AUTOSAR XML (schema 00046)
package /ComponentTypes
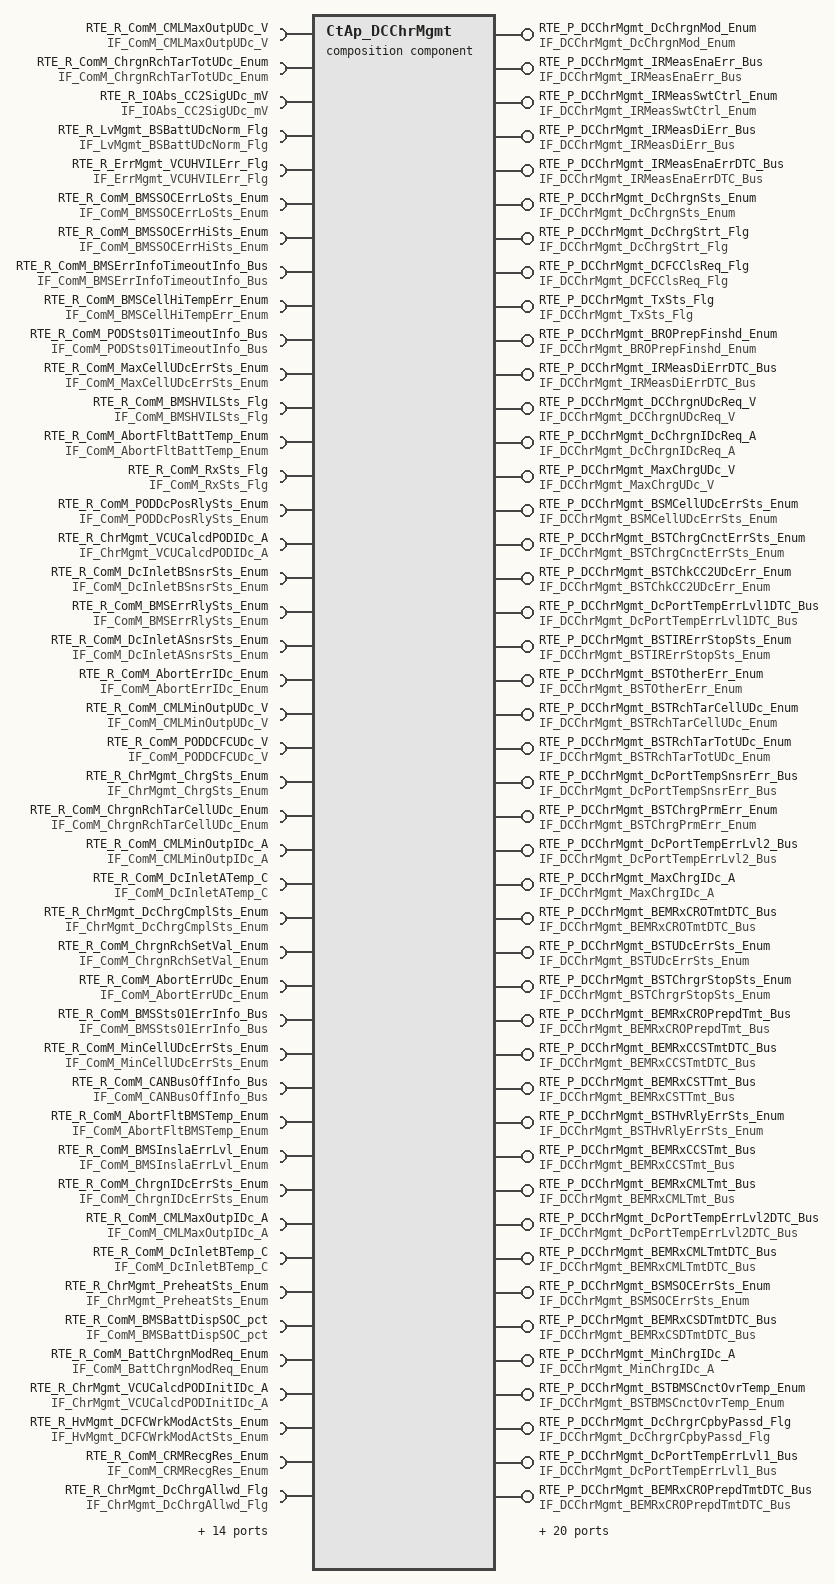
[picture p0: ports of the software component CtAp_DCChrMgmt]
  composition sw component type CtAp_DCChrMgmt
    14 x provide port:
      RTE_P_DCChrMgmt_DcChrgnMod_Enum: nonqueued-sender-com-spec{data-element=tec_DCChrMgmt_DcChrgnMod_Enum, init-value=0}, provided-interface=IF_DCChrMgmt_DcChrgnMod_Enum
      RTE_P_DCChrMgmt_IRMeasEnaErr_Bus: nonqueued-sender-com-spec{data-element=tec_DCChrMgmt_IRMeasEnaErr_Bus, init-value=fields=[DCChrMgmt_MonStatIRMeasEnaErr:0, DCChrMgmt_MonResIRMeasEnaErr:0, DCChrMgmt_ErrStatIRMeasEnaErr:0, DCChrMgmt_ErrResIRMeasEnaErr:0]}, provided-interface=IF_DCChrMgmt_IRMeasEnaErr_Bus
      RTE_P_DCChrMgmt_IRMeasSwtCtrl_Enum: nonqueued-sender-com-spec{data-element=tec_DCChrMgmt_IRMeasSwtCtrl_Enum, init-value=0}, provided-interface=IF_DCChrMgmt_IRMeasSwtCtrl_Enum
      RTE_P_DCChrMgmt_IRMeasDiErr_Bus: nonqueued-sender-com-spec{data-element=tec_DCChrMgmt_IRMeasDiErr_Bus, init-value=fields=[DCChrMgmt_MonStatIRMeasDiErr:0, DCChrMgmt_MonResIRMeasDiErr:0, DCChrMgmt_ErrStatIRMeasDiErr:0, DCChrMgmt_ErrResIRMeasDiErr:0]}, provided-interface=IF_DCChrMgmt_IRMeasDiErr_Bus
      RTE_P_DCChrMgmt_IRMeasEnaErrDTC_Bus: nonqueued-sender-com-spec{data-element=tec_DCChrMgmt_IRMeasEnaErrDTC_Bus, init-value=fields=[DCChrMgmt_MonStatIRMeasEnaErrDTC:0, DCChrMgmt_MonResIRMeasEnaErrDTC:0, DCChrMgmt_ErrStatIRMeasEnaErrDTC:0, DCChrMgmt_ErrResIRMeasEnaErrDTC:0]}, provided-interface=IF_DCChrMgmt_IRMeasEnaErrDTC_Bus
      RTE_P_DCChrMgmt_DcChrgnSts_Enum: nonqueued-sender-com-spec{data-element=tec_DCChrMgmt_DcChrgnSts_Enum, init-value=0}, provided-interface=IF_DCChrMgmt_DcChrgnSts_Enum
      RTE_P_DCChrMgmt_DcChrgStrt_Flg: nonqueued-sender-com-spec{data-element=tec_DCChrMgmt_DcChrgStrt_Flg, init-value=0}, provided-interface=IF_DCChrMgmt_DcChrgStrt_Flg
      RTE_P_DCChrMgmt_DCFCClsReq_Flg: nonqueued-sender-com-spec{data-element=tec_DCChrMgmt_DCFCClsReq_Flg, init-value=0}, provided-interface=IF_DCChrMgmt_DCFCClsReq_Flg
      RTE_P_DCChrMgmt_TxSts_Flg: provided-interface=IF_DCChrMgmt_TxSts_Flg
        provided-com-specs:
          data-element=tec_DCChrMgmt_TxBSDSts_Flg, init-value=0
          data-element=tec_DCChrMgmt_TxBEMSts_Flg, init-value=0
          data-element=tec_DCChrMgmt_TxBSMSts_Flg, init-value=0
          data-element=tec_DCChrMgmt_TxBCSSts_Flg, init-value=0
          data-element=tec_DCChrMgmt_TxBSTSts_Flg, init-value=0
          data-element=tec_DCChrMgmt_TxBCLSts_Flg, init-value=0
          data-element=tec_DCChrMgmt_TxBROSts_Flg, init-value=0
          data-element=tec_DCChrMgmt_TxBCPSts_Flg, init-value=0
          data-element=tec_DCChrMgmt_TxBRMSts_Flg, init-value=0
          data-element=tec_DCChrMgmt_TxBHMSts_Flg, init-value=0
      RTE_P_DCChrMgmt_BROPrepFinshd_Enum: nonqueued-sender-com-spec{data-element=tec_DCChrMgmt_BROPrepFinshd_Enum, init-value=0}, provided-interface=IF_DCChrMgmt_BROPrepFinshd_Enum
      RTE_P_DCChrMgmt_IRMeasDiErrDTC_Bus: nonqueued-sender-com-spec{data-element=tec_DCChrMgmt_IRMeasDiErrDTC_Bus, init-value=fields=[DCChrMgmt_MonStatIRMeasDiErrDTC:0, DCChrMgmt_MonResIRMeasDiErrDTC:0, DCChrMgmt_ErrStatIRMeasDiErrDTC:0, DCChrMgmt_ErrResIRMeasDiErrDTC:0]}, provided-interface=IF_DCChrMgmt_IRMeasDiErrDTC_Bus
      RTE_P_DCChrMgmt_DCChrgnUDcReq_V: nonqueued-sender-com-spec{data-element=tec_DCChrMgmt_DcChrgnUDcReq_V, init-value=0}, provided-interface=IF_DCChrMgmt_DCChrgnUDcReq_V
      RTE_P_DCChrMgmt_DcChrgnIDcReq_A: nonqueued-sender-com-spec{data-element=tec_DCChrMgmt_DcChrgnIDcReq_A, init-value=0}, provided-interface=IF_DCChrMgmt_DcChrgnIDcReq_A
      RTE_P_DCChrMgmt_MaxChrgUDc_V: nonqueued-sender-com-spec{data-element=tec_DCChrMgmt_MaxChrgUDc_V, init-value=0}, provided-interface=IF_DCChrMgmt_MaxChrgUDc_V
    require port RTE_R_ComM_CMLMaxOutpUDc_V: nonqueued-receiver-com-spec{data-element=tec_ComM_CMLMaxOutpUDc_V, filter=data-filter-type=ALWAYS, init-value=0}, required-interface=IF_ComM_CMLMaxOutpUDc_V
    4 x provide port:
      RTE_P_DCChrMgmt_BSMCellUDcErrSts_Enum: nonqueued-sender-com-spec{data-element=tec_DCChrMgmt_BSMCellUDcErrSts_Enum, init-value=0}, provided-interface=IF_DCChrMgmt_BSMCellUDcErrSts_Enum
      RTE_P_DCChrMgmt_BSTChrgCnctErrSts_Enum: nonqueued-sender-com-spec{data-element=tec_DCChrMgmt_BSTChrgCnctErrSts_Enum, init-value=0}, provided-interface=IF_DCChrMgmt_BSTChrgCnctErrSts_Enum
      RTE_P_DCChrMgmt_BSTChkCC2UDcErr_Enum: nonqueued-sender-com-spec{data-element=tec_DCChrMgmt_BSTChkCC2UDcErr_Enum, init-value=0}, provided-interface=IF_DCChrMgmt_BSTChkCC2UDcErr_Enum
      RTE_P_DCChrMgmt_DcPortTempErrLvl1DTC_Bus: nonqueued-sender-com-spec{data-element=tec_DCChrMgmt_DcPortTempErrLvl1DTC_Bus, init-value=fields=[DCChrMgmt_MonStatDcPortTempErrLvl1DTC:0, DCChrMgmt_MonResDcPortTempErrLvl1DTC:0, DCChrMgmt_ErrStatDcPortTempErrLvl1DTC:0, DCChrMgmt_ErrResDcPortTempErrLvl1DTC:0]}, provided-interface=IF_DCChrMgmt_DcPortTempErrLvl1DTC_Bus
    require port RTE_R_ComM_ChrgnRchTarTotUDc_Enum: nonqueued-receiver-com-spec{data-element=tec_ComM_ChrgnRchTarTotUDc_Enum, filter=data-filter-type=ALWAYS, init-value=0}, required-interface=IF_ComM_ChrgnRchTarTotUDc_Enum
    provide port RTE_P_DCChrMgmt_BSTIRErrStopSts_Enum: nonqueued-sender-com-spec{data-element=tec_DCChrMgmt_BSTIRErrStopSts_Enum, init-value=0}, provided-interface=IF_DCChrMgmt_BSTIRErrStopSts_Enum
    provide port RTE_P_DCChrMgmt_BSTOtherErr_Enum: nonqueued-sender-com-spec{data-element=tec_DCChrMgmt_BSTOtherErr_Enum, init-value=0}, provided-interface=IF_DCChrMgmt_BSTOtherErr_Enum
    require port RTE_R_IOAbs_CC2SigUDc_mV: nonqueued-receiver-com-spec{data-element=tec_IOAbs_CC2SigUDc_mV, filter=data-filter-type=ALWAYS, init-value=0}, required-interface=IF_IOAbs_CC2SigUDc_mV
    provide port RTE_P_DCChrMgmt_BSTRchTarCellUDc_Enum: nonqueued-sender-com-spec{data-element=tec_DCChrMgmt_BSTRchTarCellUDc_Enum, init-value=0}, provided-interface=IF_DCChrMgmt_BSTRchTarCellUDc_Enum
    provide port RTE_P_DCChrMgmt_BSTRchTarTotUDc_Enum: nonqueued-sender-com-spec{data-element=tec_DCChrMgmt_BSTRchTarTotUDc_Enum, init-value=0}, provided-interface=IF_DCChrMgmt_BSTRchTarTotUDc_Enum
    require port RTE_R_LvMgmt_BSBattUDcNorm_Flg: nonqueued-receiver-com-spec{data-element=tec_LvMgmt_BSBattUDcNorm_Flg, filter=data-filter-type=ALWAYS, init-value=0}, required-interface=IF_LvMgmt_BSBattUDcNorm_Flg
    provide port RTE_P_DCChrMgmt_DcPortTempSnsrErr_Bus: nonqueued-sender-com-spec{data-element=tec_DCChrMgmt_DcPortTempSnsrErr_Bus, init-value=fields=[DCChrMgmt_MonStatDcPortTempSnsrErr:0, DCChrMgmt_MonResDcPortTempSnsrErr:0, DCChrMgmt_ErrStatDcPortTempSnsrErr:0, DCChrMgmt_ErrResDcPortTempSnsrErr:0]}, provided-interface=IF_DCChrMgmt_DcPortTempSnsrErr_Bus
    provide port RTE_P_DCChrMgmt_BSTChrgPrmErr_Enum: nonqueued-sender-com-spec{data-element=tec_DCChrMgmt_BSTChrgPrmErr_Enum, init-value=0}, provided-interface=IF_DCChrMgmt_BSTChrgPrmErr_Enum
    require port RTE_R_ErrMgmt_VCUHVILErr_Flg: nonqueued-receiver-com-spec{data-element=tec_ErrMgmt_VCUHVILErr_Flg, filter=data-filter-type=ALWAYS, init-value=0}, required-interface=IF_ErrMgmt_VCUHVILErr_Flg
    require port RTE_R_ComM_BMSSOCErrLoSts_Enum: nonqueued-receiver-com-spec{data-element=tec_ComM_BMSSOCLoErrSts_Enum, filter=data-filter-type=ALWAYS, init-value=0}, required-interface=IF_ComM_BMSSOCErrLoSts_Enum
    4 x provide port:
      RTE_P_DCChrMgmt_DcPortTempErrLvl2_Bus: nonqueued-sender-com-spec{data-element=tec_DCChrMgmt_DcPortTempErrLvl2_Bus, init-value=fields=[DCChrMgmt_MonStatDcPortTempErrLvl2:0, DCChrMgmt_MonResDcPortTempErrLvl2:0, DCChrMgmt_ErrStatDcPortTempErrLvl2:0, DCChrMgmt_ErrResDcPortTempErrLvl2:0]}, provided-interface=IF_DCChrMgmt_DcPortTempErrLvl2_Bus
      RTE_P_DCChrMgmt_MaxChrgIDc_A: nonqueued-sender-com-spec{data-element=tec_DCChrMgmt_MaxChrgIDc_A, init-value=0}, provided-interface=IF_DCChrMgmt_MaxChrgIDc_A
      RTE_P_DCChrMgmt_BEMRxCROTmtDTC_Bus: nonqueued-sender-com-spec{data-element=tec_DCChrMgmt_BEMRxCROTmtDTC_Bus, init-value=fields=[DCChrMgmt_MonStatBEMRxCROTmtDTC:0, DCChrMgmt_MonResBEMRxCROTmtDTC:0, DCChrMgmt_ErrStatBEMRxCROTmtDTC:0, DCChrMgmt_ErrResBEMRxCROTmtDTC:0]}, provided-interface=IF_DCChrMgmt_BEMRxCROTmtDTC_Bus
      RTE_P_DCChrMgmt_BSTUDcErrSts_Enum: nonqueued-sender-com-spec{data-element=tec_DCChrMgmt_BSTUDcErrSts_Enum, init-value=0}, provided-interface=IF_DCChrMgmt_BSTUDcErrSts_Enum
    require port RTE_R_ComM_BMSSOCErrHiSts_Enum: nonqueued-receiver-com-spec{data-element=tec_ComM_BMSSOCHiErrSts_Enum, filter=data-filter-type=ALWAYS, init-value=0}, required-interface=IF_ComM_BMSSOCErrHiSts_Enum
    provide port RTE_P_DCChrMgmt_BSTChrgrStopSts_Enum: nonqueued-sender-com-spec{data-element=tec_DCChrMgmt_BSTChrgrStopSts_Enum, init-value=0}, provided-interface=IF_DCChrMgmt_BSTChrgrStopSts_Enum
    provide port RTE_P_DCChrMgmt_BEMRxCROPrepdTmt_Bus: nonqueued-sender-com-spec{data-element=tec_DCChrMgmt_BEMRxCROPrepdTmt_Bus, init-value=fields=[DCChrMgmt_MonStatBEMRxCROPrepdTmt:0, DCChrMgmt_MonResBEMRxCROPrepdTmt:0, DCChrMgmt_ErrStatBEMRxCROPrepdTmt:0, DCChrMgmt_ErrResBEMRxCROPrepdTmt:0]}, provided-interface=IF_DCChrMgmt_BEMRxCROPrepdTmt_Bus
    require port RTE_R_ComM_BMSErrInfoTimeoutInfo_Bus: nonqueued-receiver-com-spec{data-element=tec_ComM_BMSErrInfoTimeoutInfo_Bus, filter=data-filter-type=ALWAYS, init-value=fields=[ComM_MonStatBMSErrInfoTimeoutInfo:0, ComM_MonResBMSErrInfoTimeoutInfo:0, ComM_ErrStatBMSErrInfoTimeoutInfo:0, ComM_ErrResBMSErrInfoTimeoutInfo:0]}, required-interface=IF_ComM_BMSErrInfoTimeoutInfo_Bus
    provide port RTE_P_DCChrMgmt_BEMRxCCSTmtDTC_Bus: nonqueued-sender-com-spec{data-element=tec_DCChrMgmt_BEMRxCCSTmtDTC_Bus, init-value=fields=[DCChrMgmt_MonStatBEMRxCCSTmtDTC:0, DCChrMgmt_MonResBEMRxCCSTmtDTC:0, DCChrMgmt_ErrStatBEMRxCCSTmtDTC:0, DCChrMgmt_ErrResBEMRxCCSTmtDTC:0]}, provided-interface=IF_DCChrMgmt_BEMRxCCSTmtDTC_Bus
    provide port RTE_P_DCChrMgmt_BEMRxCSTTmt_Bus: nonqueued-sender-com-spec{data-element=tec_DCChrMgmt_BEMRxCSTTmt_Bus, init-value=fields=[DCChrMgmt_MonStatBEMRxCSTTmt:0, DCChrMgmt_MonResBEMRxCSTTmt:0, DCChrMgmt_ErrStatBEMRxCSTTmt:0, DCChrMgmt_ErrResBEMRxCSTTmt:0]}, provided-interface=IF_DCChrMgmt_BEMRxCSTTmt_Bus
    4 x require port:
      RTE_R_ComM_BMSCellHiTempErr_Enum: nonqueued-receiver-com-spec{data-element=tec_ComM_BMSCellHiTempErr_Enum, filter=data-filter-type=ALWAYS, init-value=0}, required-interface=IF_ComM_BMSCellHiTempErr_Enum
      RTE_R_ComM_PODSts01TimeoutInfo_Bus: nonqueued-receiver-com-spec{data-element=tec_ComM_PODSts01TimeoutInfo_Bus, filter=data-filter-type=ALWAYS, init-value=fields=[ComM_MonStatPODSts01TimeoutInfo:0, ComM_MonResPODSts01TimeoutInfo:0, ComM_ErrStatPODSts01TimeoutInfo:0, ComM_ErrResPODSts01TimeoutInfo:0]}, required-interface=IF_ComM_PODSts01TimeoutInfo_Bus
      RTE_R_ComM_MaxCellUDcErrSts_Enum: nonqueued-receiver-com-spec{data-element=tec_ComM_MaxCellUDcErrSts_Enum, filter=data-filter-type=ALWAYS, init-value=0}, required-interface=IF_ComM_MaxCellUDcErrSts_Enum
      RTE_R_ComM_BMSHVILSts_Flg: nonqueued-receiver-com-spec{data-element=tec_ComM_BMSHVILSts_Flg, filter=data-filter-type=ALWAYS, init-value=0}, required-interface=IF_ComM_BMSHVILSts_Flg
    provide port RTE_P_DCChrMgmt_BSTHvRlyErrSts_Enum: nonqueued-sender-com-spec{data-element=tec_DCChrMgmt_BSTHvRlyErrSts_Enum, init-value=0}, provided-interface=IF_DCChrMgmt_BSTHvRlyErrSts_Enum
    provide port RTE_P_DCChrMgmt_BEMRxCCSTmt_Bus: nonqueued-sender-com-spec{data-element=tec_DCChrMgmt_BEMRxCCSTmt_Bus, init-value=fields=[DCChrMgmt_MonStatBEMRxCCSTmt:0, DCChrMgmt_MonResBEMRxCCSTmt:0, DCChrMgmt_ErrStatBEMRxCCSTmt:0, DCChrMgmt_ErrResBEMRxCCSTmt:0]}, provided-interface=IF_DCChrMgmt_BEMRxCCSTmt_Bus
    provide port RTE_P_DCChrMgmt_BEMRxCMLTmt_Bus: nonqueued-sender-com-spec{data-element=tec_DCChrMgmt_BEMRxCMLTmt_Bus, init-value=fields=[DCChrMgmt_MonStatBEMRxCMLTmt:0, DCChrMgmt_MonResBEMRxCMLTmt:0, DCChrMgmt_ErrStatBEMRxCMLTmt:0, DCChrMgmt_ErrResBEMRxCMLTmt:0]}, provided-interface=IF_DCChrMgmt_BEMRxCMLTmt_Bus
    require port RTE_R_ComM_AbortFltBattTemp_Enum: nonqueued-receiver-com-spec{data-element=tec_ComM_AbortFltBattTemp_Enum, filter=data-filter-type=ALWAYS, init-value=0}, required-interface=IF_ComM_AbortFltBattTemp_Enum
    require port RTE_R_ComM_RxSts_Flg: required-interface=IF_ComM_RxSts_Flg
      required-com-specs:
        data-element=tec_ComM_RxCROSts_Flg, filter=data-filter-type=ALWAYS, init-value=0
        data-element=tec_ComM_RxCEMSts_Flg, filter=data-filter-type=ALWAYS, init-value=0
        data-element=tec_ComM_RxCHMSts_Flg, filter=data-filter-type=ALWAYS, init-value=0
        data-element=tec_ComM_RxCSTSts_Flg, filter=data-filter-type=ALWAYS, init-value=0
        data-element=tec_ComM_RxCSDSts_Flg, filter=data-filter-type=ALWAYS, init-value=0
        data-element=tec_ComM_RxCCSSts_Flg, filter=data-filter-type=ALWAYS, init-value=0
        data-element=tec_ComM_RxCMLSts_Flg, filter=data-filter-type=ALWAYS, init-value=0
        data-element=tec_ComM_RxCRMSts_Flg, filter=data-filter-type=ALWAYS, init-value=0
    require port RTE_R_ComM_PODDcPosRlySts_Enum: nonqueued-receiver-com-spec{data-element=tec_ComM_PODDcPosRlySts_Enum, filter=data-filter-type=ALWAYS, init-value=0}, required-interface=IF_ComM_PODDcPosRlySts_Enum
    provide port RTE_P_DCChrMgmt_DcPortTempErrLvl2DTC_Bus: nonqueued-sender-com-spec{data-element=tec_DCChrMgmt_DcPortTempErrLvl2DTC_Bus, init-value=fields=[DCChrMgmt_MonStatDcPortTempErrLvl2DTC:0, DCChrMgmt_MonResDcPortTempErrLvl2DTC:0, DCChrMgmt_ErrStatDcPortTempErrLvl2DTC:0, DCChrMgmt_ErrResDcPortTempErrLvl2DTC:0]}, provided-interface=IF_DCChrMgmt_DcPortTempErrLvl2DTC_Bus
    provide port RTE_P_DCChrMgmt_BEMRxCMLTmtDTC_Bus: nonqueued-sender-com-spec{data-element=tec_DCChrMgmt_BEMRxCMLTmtDTC_Bus, init-value=fields=[DCChrMgmt_MonStatBEMRxCMLTmtDTC:0, DCChrMgmt_MonResBEMRxCMLTmtDTC:0, DCChrMgmt_ErrStatBEMRxCMLTmtDTC:0, DCChrMgmt_ErrResBEMRxCMLTmtDTC:0]}, provided-interface=IF_DCChrMgmt_BEMRxCMLTmtDTC_Bus
    require port RTE_R_ChrMgmt_VCUCalcdPODIDc_A: nonqueued-receiver-com-spec{data-element=tec_ChrMgmt_VCUCalcdPODIDc_A, filter=data-filter-type=ALWAYS, init-value=0}, required-interface=IF_ChrMgmt_VCUCalcdPODIDc_A
    require port RTE_R_ComM_DcInletBSnsrSts_Enum: nonqueued-receiver-com-spec{data-element=tec_ComM_DcInletBSnsrSts_Enum, filter=data-filter-type=ALWAYS, init-value=0}, required-interface=IF_ComM_DcInletBSnsrSts_Enum
    provide port RTE_P_DCChrMgmt_BSMSOCErrSts_Enum: nonqueued-sender-com-spec{data-element=tec_DCChrMgmt_BSMSOCErrSts_Enum, init-value=0}, provided-interface=IF_DCChrMgmt_BSMSOCErrSts_Enum
    require port RTE_R_ComM_BMSErrRlySts_Enum: nonqueued-receiver-com-spec{data-element=tec_ComM_BMSErrRlySts_Enum, filter=data-filter-type=ALWAYS, init-value=0}, required-interface=IF_ComM_BMSErrRlySts_Enum
    require port RTE_R_ComM_DcInletASnsrSts_Enum: nonqueued-receiver-com-spec{data-element=tec_ComM_DcInletASnsrSts_Enum, filter=data-filter-type=ALWAYS, init-value=0}, required-interface=IF_ComM_DcInletASnsrSts_Enum
    provide port RTE_P_DCChrMgmt_BEMRxCSDTmtDTC_Bus: nonqueued-sender-com-spec{data-element=tec_DCChrMgmt_BEMRxCSDTmtDTC_Bus, init-value=fields=[DCChrMgmt_MonStatBEMRxCSDTmtDTC:0, DCChrMgmt_MonResBEMRxCSDTmtDTC:0, DCChrMgmt_ErrStatBEMRxCSDTmtDTC:0, DCChrMgmt_ErrResBEMRxCSDTmtDTC:0]}, provided-interface=IF_DCChrMgmt_BEMRxCSDTmtDTC_Bus
    require port RTE_R_ComM_AbortErrIDc_Enum: nonqueued-receiver-com-spec{data-element=tec_ComM_AbortErrIDc_Enum, filter=data-filter-type=ALWAYS, init-value=0}, required-interface=IF_ComM_AbortErrIDc_Enum
    require port RTE_R_ComM_CMLMinOutpUDc_V: nonqueued-receiver-com-spec{data-element=tec_ComM_CMLMinOutpUDc_V, filter=data-filter-type=ALWAYS, init-value=0}, required-interface=IF_ComM_CMLMinOutpUDc_V
    require port RTE_R_ComM_PODDCFCUDc_V: nonqueued-receiver-com-spec{data-element=tec_ComM_PODDCFCUDc_V, filter=data-filter-type=ALWAYS, init-value=0}, required-interface=IF_ComM_PODDCFCUDc_V
    provide port RTE_P_DCChrMgmt_MinChrgIDc_A: nonqueued-sender-com-spec{data-element=tec_DCChrMgmt_MinChrgIDc_A, init-value=0}, provided-interface=IF_DCChrMgmt_MinChrgIDc_A
    require port RTE_R_ChrMgmt_ChrgSts_Enum: nonqueued-receiver-com-spec{data-element=tec_ChrMgmt_ChrgSts_Enum, filter=data-filter-type=ALWAYS, init-value=0}, required-interface=IF_ChrMgmt_ChrgSts_Enum
    provide port RTE_P_DCChrMgmt_BSTBMSCnctOvrTemp_Enum: nonqueued-sender-com-spec{data-element=tec_DCChrMgmt_BSTBMSCnctOvrTemp_Enum, init-value=0}, provided-interface=IF_DCChrMgmt_BSTBMSCnctOvrTemp_Enum
    require port RTE_R_ComM_ChrgnRchTarCellUDc_Enum: nonqueued-receiver-com-spec{data-element=tec_ComM_ChrgnRchTarCellUDc_Enum, filter=data-filter-type=ALWAYS, init-value=0}, required-interface=IF_ComM_ChrgnRchTarCellUDc_Enum
    require port RTE_R_ComM_CMLMinOutpIDc_A: nonqueued-receiver-com-spec{data-element=tec_ComM_CMLMinOutpIDc_A, filter=data-filter-type=ALWAYS, init-value=0}, required-interface=IF_ComM_CMLMinOutpIDc_A
    provide port RTE_P_DCChrMgmt_DcChrgrCpbyPassd_Flg: nonqueued-sender-com-spec{data-element=tec_DCChrMgmt_DcChrgrCpbyPassd_Flg, init-value=0}, provided-interface=IF_DCChrMgmt_DcChrgrCpbyPassd_Flg
    provide port RTE_P_DCChrMgmt_DcPortTempErrLvl1_Bus: nonqueued-sender-com-spec{data-element=tec_DCChrMgmt_DcPortTempErrLvl1_Bus, init-value=fields=[DCChrMgmt_MonStatDcPortTempErrLvl1:0, DCChrMgmt_MonResDcPortTempErrLvl1:0, DCChrMgmt_ErrStatDcPortTempErrLvl1:0, DCChrMgmt_ErrResDcPortTempErrLvl1:0]}, provided-interface=IF_DCChrMgmt_DcPortTempErrLvl1_Bus
    require port RTE_R_ComM_DcInletATemp_C: nonqueued-receiver-com-spec{data-element=tec_ComM_DcInletATemp_C, filter=data-filter-type=ALWAYS, init-value=0}, required-interface=IF_ComM_DcInletATemp_C
    provide port RTE_P_DCChrMgmt_BEMRxCROPrepdTmtDTC_Bus: nonqueued-sender-com-spec{data-element=tec_DCChrMgmt_BEMRxCROPrepdTmtDTC_Bus, init-value=fields=[DCChrMgmt_MonStatBEMRxCROPrepdTmtDTC:0, DCChrMgmt_MonResBEMRxCROPrepdTmtDTC:0, DCChrMgmt_ErrStatBEMRxCROPrepdTmtDTC:0, DCChrMgmt_ErrResBEMRxCROPrepdTmtDTC:0]}, provided-interface=IF_DCChrMgmt_BEMRxCROPrepdTmtDTC_Bus
    require port RTE_R_ChrMgmt_DcChrgCmplSts_Enum: nonqueued-receiver-com-spec{data-element=tec_ChrMgmt_DcChrgCmplSts_Enum, filter=data-filter-type=ALWAYS, init-value=0}, required-interface=IF_ChrMgmt_DcChrgCmplSts_Enum
    provide port RTE_P_DCChrMgmt_BSTOutpCnctOvrTemp_Enum: nonqueued-sender-com-spec{data-element=tec_DCChrMgmt_BSTOutpCnctOvrTemp_Enum, init-value=0}, provided-interface=IF_DCChrMgmt_BSTOutpCnctOvrTemp_Enum
    provide port RTE_P_DCChrMgmt_BEMRxCSDTmt_Bus: nonqueued-sender-com-spec{data-element=tec_DCChrMgmt_BEMRxCSDTmt_Bus, init-value=fields=[DCChrMgmt_MonStatBEMRxCSDTmt:0, DCChrMgmt_MonResBEMRxCSDTmt:0, DCChrMgmt_ErrStatBEMRxCSDTmt:0, DCChrMgmt_ErrResBEMRxCSDTmt:0]}, provided-interface=IF_DCChrMgmt_BEMRxCSDTmt_Bus
    require port RTE_R_ComM_ChrgnRchSetVal_Enum: nonqueued-receiver-com-spec{data-element=tec_ComM_ChrgnRchSetVal_Enum, filter=data-filter-type=ALWAYS, init-value=0}, required-interface=IF_ComM_ChrgnRchSetVal_Enum
    7 x provide port:
      RTE_P_DCChrMgmt_MinChrgUDc_V: nonqueued-sender-com-spec{data-element=tec_DCChrMgmt_MinChrgUDc_V, init-value=0}, provided-interface=IF_DCChrMgmt_MinChrgUDc_V
      RTE_P_DCChrMgmt_BSTRchTarSOC_Enum: nonqueued-sender-com-spec{data-element=tec_DCChrMgmt_BSTRchTarSOC_Enum, init-value=0}, provided-interface=IF_DCChrMgmt_BSTRchTarSOC_Enum
      RTE_P_DCChrMgmt_BEMRxCRMPrepdTmtDTC_Bus: nonqueued-sender-com-spec{data-element=tec_DCChrMgmt_BEMRxCRMPrepdTmtDTC_Bus, init-value=fields=[DCChrMgmt_MonStatBEMRxCRMPrepdTmtDTC:0, DCChrMgmt_MonResBEMRxCRMPrepdTmtDTC:0, DCChrMgmt_ErrStatBEMRxCRMPrepdTmtDTC:0, DCChrMgmt_ErrResBEMRxCRMPrepdTmtDTC:0]}, provided-interface=IF_DCChrMgmt_BEMRxCRMPrepdTmtDTC_Bus
      RTE_P_DCChrMgmt_BSMOutpCnctErrSts_Enum: nonqueued-sender-com-spec{data-element=tec_DCChrMgmt_BSMOutpCnctErrSts_Enum, init-value=0}, provided-interface=IF_DCChrMgmt_BSMOutpCnctErrSts_Enum
      RTE_P_DCChrMgmt_BSTBattOvrTempErr_Enum: nonqueued-sender-com-spec{data-element=tec_DCChrMgmt_BSTBattOvrTempErr_Enum, init-value=0}, provided-interface=IF_DCChrMgmt_BSTBattOvrTempErr_Enum
      RTE_P_DCChrMgmt_BSMIRErrSts_Enum: nonqueued-sender-com-spec{data-element=tec_DCChrMgmt_BSMIRErrSts_Enum, init-value=0}, provided-interface=IF_DCChrMgmt_BSMIRErrSts_Enum
      RTE_P_DCChrMgmt_BSMBattTempHiErrSts_Enum: nonqueued-sender-com-spec{data-element=tec_DCChrMgmt_BSMBattTempHiErrSts_Enum, init-value=0}, provided-interface=IF_DCChrMgmt_BSMBattTempHiErrSts_Enum
    require port RTE_R_ComM_AbortErrUDc_Enum: nonqueued-receiver-com-spec{data-element=tec_ComM_AbortErrUDc_Enum, filter=data-filter-type=ALWAYS, init-value=0}, required-interface=IF_ComM_AbortErrUDc_Enum
    provide port RTE_P_DCChrMgmt_BSMChrgnIDcErrSts_Enum: nonqueued-sender-com-spec{data-element=tec_DCChrMgmt_BSMChrgnIDcErrSts_Enum, init-value=0}, provided-interface=IF_DCChrMgmt_BSMChrgnIDcErrSts_Enum
    provide port RTE_P_DCChrMgmt_BEMTxReqSts_Enum: nonqueued-sender-com-spec{data-element=tec_DCChrMgmt_BEMTxReqSts_Enum, init-value=0}, provided-interface=IF_DCChrMgmt_BEMTxReqSts_Enum
    require port RTE_R_ComM_BMSSts01ErrInfo_Bus: required-interface=IF_ComM_BMSSts01ErrInfo_Bus
      required-com-specs:
        data-element=tec_ComM_BMSSts01TimeoutInfo_Bus, filter=data-filter-type=ALWAYS, init-value=fields=[ComM_MonStatBMSSts01TimeoutInfo:0, ComM_MonResBMSSts01TimeoutInfo:0, ComM_ErrStatBMSSts01TimeoutInfo:0, ComM_ErrResBMSSts01TimeoutInfo:0]
        data-element=tec_ComM_BMSSts01CRCDTCInfo_Bus, filter=data-filter-type=ALWAYS, init-value=fields=[ComM_MonStatBMSSts01CRCDTCErrorInfo:0, ComM_MonResBMSSts01CRCDTCErrorInfo:0, ComM_ErrStatBMSSts01CRCDTCErrorInfo:0, ComM_ErrResBMSSts01CRCDTCErrorInfo:0]
        data-element=tec_ComM_BMSSts01CRCInfo_Bus, filter=data-filter-type=ALWAYS, init-value=fields=[ComM_MonStatBMSSts01CRCErrorInfo:0, ComM_MonResBMSSts01CRCErrorInfo:0, ComM_ErrStatBMSSts01CRCErrorInfo:0, ComM_ErrResBMSSts01CRCErrorInfo:0]
        data-element=tec_ComM_BMSSts01TimeoutDTCInfo_Bus, filter=data-filter-type=ALWAYS, init-value=fields=[ComM_MonStatBMSSts01TimeoutDTCErrorInfo:0, ComM_MonResBMSSts01TimeoutDTCErrorInfo:0, ComM_ErrStatBMSSts01TimeoutDTCErrorInfo:0, ComM_ErrResBMSSts01TimeoutDTCErrorInfo:0]
        data-element=tec_ComM_BMSSts01E2ETimeoutInfo_Bus, filter=data-filter-type=ALWAYS, init-value=fields=[ComM_MonStatBMSSts01E2ETimeoutInfo:0, ComM_MonResBMSSts01E2ETimeoutInfo:0, ComM_ErrStatBMSSts01E2ETimeoutInfo:0, ComM_ErrResBMSSts01E2ETimeoutInfo:0]
    require port RTE_R_ComM_MinCellUDcErrSts_Enum: nonqueued-receiver-com-spec{data-element=tec_ComM_MinCellUDcErrSts_Enum, filter=data-filter-type=ALWAYS, init-value=0}, required-interface=IF_ComM_MinCellUDcErrSts_Enum
    require port RTE_R_ComM_CANBusOffInfo_Bus: required-interface=IF_ComM_CANBusOffInfo_Bus
      required-com-specs:
        data-element=tec_ComM_EPTCANBusOffInfo_Bus, filter=data-filter-type=ALWAYS, init-value=fields=[ComM_MonStatEPTCANBusOffInfo:0, ComM_MonResEPTCANBusOffInfo:0, ComM_ErrStatEPTCANBusOffInfo:0, ComM_ErrResEPTCANBusOffInfo:0]
        data-element=tec_ComM_CHCANBusOffInfo_Bus, filter=data-filter-type=ALWAYS, init-value=fields=[ComM_MonStatCHCANBusOffInfo:0, ComM_MonResCHCANBusOffInfo:0, ComM_ErrStatCHCANBusOffInfo:0, ComM_ErrResCHCANBusOffInfo:0]
        data-element=tec_ComM_EPTCANBusOffDTCInfo_Bus, filter=data-filter-type=ALWAYS, init-value=fields=[ComM_MonStatEPTCANBusOffDTCInfo:0, ComM_MonResEPTCANBusOffDTCInfo:0, ComM_ErrStatEPTCANBusOffDTCInfo:0, ComM_ErrResEPTCANBusOffDTCInfo:0]
        data-element=tec_ComM_CHCANBusOffDTCInfo_Bus, filter=data-filter-type=ALWAYS, init-value=fields=[ComM_MonStatCHCANBusOffDTCInfo:0, ComM_MonResCHCANBusOffDTCInfo:0, ComM_ErrStatCHCANBusOffDTCInfo:0, ComM_ErrResCHCANBusOffDTCInfo:0]
    provide port RTE_P_DCChrMgmt_BEMRxCRMTmtDTC_Bus: nonqueued-sender-com-spec{data-element=tec_DCChrMgmt_BEMRxCRMTmtDTC_Bus, init-value=fields=[DCChrMgmt_MonStatBEMRxCRMTmtDTC:0, DCChrMgmt_MonResBEMRxCRMTmtDTC:0, DCChrMgmt_ErrStatBEMRxCRMTmtDTC:0, DCChrMgmt_ErrResBEMRxCRMTmtDTC:0]}, provided-interface=IF_DCChrMgmt_BEMRxCRMTmtDTC_Bus
    require port RTE_R_ComM_AbortFltBMSTemp_Enum: nonqueued-receiver-com-spec{data-element=tec_ComM_AbortFltBMSTemp_Enum, filter=data-filter-type=ALWAYS, init-value=0}, required-interface=IF_ComM_AbortFltBMSTemp_Enum
    provide port RTE_P_DCChrMgmt_BSTIDcErrSts_Enum: nonqueued-sender-com-spec{data-element=tec_DCChrMgmt_BSTIDcErrSts_Enum, init-value=0}, provided-interface=IF_DCChrMgmt_BSTIDcErrSts_Enum
    provide port RTE_P_DCChrMgmt_BEMRxCRMTmt_Bus: nonqueued-sender-com-spec{data-element=tec_DCChrMgmt_BEMRxCRMTmt_Bus, init-value=fields=[DCChrMgmt_MonStatBEMRxCRMTmt:0, DCChrMgmt_MonResBEMRxCRMTmt:0, DCChrMgmt_ErrStatBEMRxCRMTmt:0, DCChrMgmt_ErrResBEMRxCRMTmt:0]}, provided-interface=IF_DCChrMgmt_BEMRxCRMTmt_Bus
    require port RTE_R_ComM_BMSInslaErrLvl_Enum: nonqueued-receiver-com-spec{data-element=tec_ComM_BMSInslaErrLvl_Enum, filter=data-filter-type=ALWAYS, init-value=0}, required-interface=IF_ComM_BMSInslaErrLvl_Enum
    require port RTE_R_ComM_ChrgnIDcErrSts_Enum: nonqueued-receiver-com-spec{data-element=tec_ComM_ChrgnIDcErrSts_Enum, filter=data-filter-type=ALWAYS, init-value=0}, required-interface=IF_ComM_ChrgnIDcErrSts_Enum
    require port RTE_R_ComM_CMLMaxOutpIDc_A: nonqueued-receiver-com-spec{data-element=tec_ComM_CMLMaxOutpIDc_A, filter=data-filter-type=ALWAYS, init-value=0}, required-interface=IF_ComM_CMLMaxOutpIDc_A
    provide port RTE_P_DCChrMgmt_BEMRxCROTmt_Bus: nonqueued-sender-com-spec{data-element=tec_DCChrMgmt_BEMRxCROTmt_Bus, init-value=fields=[DCChrMgmt_MonStatBEMRxCROTmt:0, DCChrMgmt_MonResBEMRxCROTmt:0, DCChrMgmt_ErrStatBEMRxCROTmt:0, DCChrMgmt_ErrResBEMRxCROTmt:0]}, provided-interface=IF_DCChrMgmt_BEMRxCROTmt_Bus
    provide port RTE_P_DCChrMgmt_DcPortTempSnsrErrDTC_Bus: nonqueued-sender-com-spec{data-element=tec_DCChrMgmt_DcPortTempSnsrErrDTC_Bus, init-value=fields=[DCChrMgmt_MonStatDcPortTempSnsrErrDTC:0, DCChrMgmt_MonResDcPortTempSnsrErrDTC:0, DCChrMgmt_ErrStatDcPortTempSnsrErrDTC:0, DCChrMgmt_ErrResDcPortTempSnsrErrDTC:0]}, provided-interface=IF_DCChrMgmt_DcPortTempSnsrErrDTC_Bus
    require port RTE_R_ComM_DcInletBTemp_C: nonqueued-receiver-com-spec{data-element=tec_ComM_DcInletBTemp_C, filter=data-filter-type=ALWAYS, init-value=0}, required-interface=IF_ComM_DcInletBTemp_C
    provide port RTE_P_DCChrMgmt_BSMChrgAllwbl_Flg: nonqueued-sender-com-spec{data-element=tec_DCChrMgmt_BSMChrgAllwbl_Flg, init-value=0}, provided-interface=IF_DCChrMgmt_BSMChrgAllwbl_Flg
    provide port RTE_P_DCChrMgmt_BEMRxCRMPrepdTmt_Bus: nonqueued-sender-com-spec{data-element=tec_DCChrMgmt_BEMRxCRMPrepdTmt_Bus, init-value=fields=[DCChrMgmt_MonStatBEMRxCRMPrepdTmt:0, DCChrMgmt_MonResBEMRxCRMPrepdTmt:0, DCChrMgmt_ErrStatBEMRxCRMPrepdTmt:0, DCChrMgmt_ErrResBEMRxCRMPrepdTmt:0]}, provided-interface=IF_DCChrMgmt_BEMRxCRMPrepdTmt_Bus
    provide port RTE_P_DCChrMgmt_BEMRxCSTTmtDTC_Bus: nonqueued-sender-com-spec{data-element=tec_DCChrMgmt_BEMRxCSTTmtDTC_Bus, init-value=fields=[DCChrMgmt_MonStatBEMRxCSTTmtDTC:0, DCChrMgmt_MonResBEMRxCSTTmtDTC:0, DCChrMgmt_ErrStatBEMRxCSTTmtDTC:0, DCChrMgmt_ErrResBEMRxCSTTmtDTC:0]}, provided-interface=IF_DCChrMgmt_BEMRxCSTTmtDTC_Bus
    19 x require port:
      RTE_R_ChrMgmt_PreheatSts_Enum: nonqueued-receiver-com-spec{data-element=tec_ChrMgmt_PreheatSts_Enum, filter=data-filter-type=ALWAYS, init-value=0}, required-interface=IF_ChrMgmt_PreheatSts_Enum
      RTE_R_ComM_BMSBattDispSOC_pct: nonqueued-receiver-com-spec{data-element=tec_ComM_BMSBattDispSOC_pct, filter=data-filter-type=ALWAYS, init-value=0}, required-interface=IF_ComM_BMSBattDispSOC_pct
      RTE_R_ComM_BattChrgnModReq_Enum: nonqueued-receiver-com-spec{data-element=tec_ComM_BattChrgnModReq_Enum, filter=data-filter-type=ALWAYS, init-value=0}, required-interface=IF_ComM_BattChrgnModReq_Enum
      RTE_R_ChrMgmt_VCUCalcdPODInitIDc_A: nonqueued-receiver-com-spec{data-element=tec_ChrMgmt_VCUCalcdPODInitIDc_A, filter=data-filter-type=ALWAYS, init-value=0}, required-interface=IF_ChrMgmt_VCUCalcdPODInitIDc_A
      RTE_R_HvMgmt_DCFCWrkModActSts_Enum: nonqueued-receiver-com-spec{data-element=tec_HvMgmt_DCFCWrkModActSts_Enum, filter=data-filter-type=ALWAYS, init-value=0}, required-interface=IF_HvMgmt_DCFCWrkModActSts_Enum
      RTE_R_ComM_CRMRecgRes_Enum: nonqueued-receiver-com-spec{data-element=tec_ComM_CRMRecgRes_Enum, filter=data-filter-type=ALWAYS, init-value=0}, required-interface=IF_ComM_CRMRecgRes_Enum
      RTE_R_ChrMgmt_DcChrgAllwd_Flg: nonqueued-receiver-com-spec{data-element=tec_ChrMgmt_DcChrgAllwd_Flg, filter=data-filter-type=ALWAYS, init-value=0}, required-interface=IF_ChrMgmt_DcChrgAllwd_Flg
      RTE_R_ComM_BMSIRDetnSts_Enum: nonqueued-receiver-com-spec{data-element=tec_ComM_BMSIRDetnSts_Enum, filter=data-filter-type=ALWAYS, init-value=0}, required-interface=IF_ComM_BMSIRDetnSts_Enum
      RTE_R_ComM_CROPrepRdy_Enum: nonqueued-receiver-com-spec{data-element=tec_ComM_CROPrepRdy_Enum, filter=data-filter-type=ALWAYS, init-value=0}, required-interface=IF_ComM_CROPrepRdy_Enum
      RTE_R_ErrMgmt_DcPause_Flg: nonqueued-receiver-com-spec{data-element=tec_ErrMgmt_DcPause_Flg, filter=data-filter-type=ALWAYS, init-value=0}, required-interface=IF_ErrMgmt_DcPause_Flg
      RTE_R_ComM_BMSBattAllowChrgIDc_A: nonqueued-receiver-com-spec{data-element=tec_ComM_BMSBattAllowChrgIDc_A, filter=data-filter-type=ALWAYS, init-value=0}, required-interface=IF_ComM_BMSBattAllowChrgIDc_A
      RTE_R_ComM_BMSBattLnkUDc_V: nonqueued-receiver-com-spec{data-element=tec_ComM_BMSBattLnkUDc_V, filter=data-filter-type=ALWAYS, init-value=0}, required-interface=IF_ComM_BMSBattLnkUDc_V
      RTE_R_ComM_BMSBattPckUDc_V: nonqueued-receiver-com-spec{data-element=tec_ComM_BMSBattPckUDc_V, filter=data-filter-type=ALWAYS, init-value=0}, required-interface=IF_ComM_BMSBattPckUDc_V
      RTE_R_EgyMgmt_DCDCPwrCnsCalcn_Kw: nonqueued-receiver-com-spec{data-element=tec_EgyMgmt_DCDCPwrCnsCalcn_Kw, filter=data-filter-type=ALWAYS, init-value=0}, required-interface=IF_EgyMgmt_DCDCPwrCnsCalcn_Kw
      RTE_R_EgyMgmt_PackPTCPwrCnsCalcn_Kw: nonqueued-receiver-com-spec{data-element=tec_EgyMgmt_PackPTCPwrCnsCalcn_Kw, filter=data-filter-type=ALWAYS, init-value=0}, required-interface=IF_EgyMgmt_PackPTCPwrCnsCalcn_Kw
      RTE_R_EgyMgmt_ACSysPwrCnsCalcn_Kw: nonqueued-receiver-com-spec{data-element=tec_EgyMgmt_ACSysPwrCnsCalcn_Kw, filter=data-filter-type=ALWAYS, init-value=0}, required-interface=IF_EgyMgmt_ACSysPwrCnsCalcn_Kw
      RTE_R_ComM_BMSBattMaxChrgnUDc_V: nonqueued-receiver-com-spec{data-element=tec_ComM_BMSBattMaxChrgnUDc_V, filter=data-filter-type=ALWAYS, init-value=0}, required-interface=IF_ComM_BMSBattMaxChrgnUDc_V
      RTE_R_ModMgmt_HvSts_Enum: nonqueued-receiver-com-spec{data-element=tec_ModMgmt_HvSts_Enum, filter=data-filter-type=ALWAYS, init-value=0}, required-interface=IF_ModMgmt_HvSts_Enum
      RTE_R_DiagApp_DisableDCMReqInfo: nonqueued-receiver-com-spec{data-element=tec_DiagApp_DisableDCMReqInfo, filter=data-filter-type=ALWAYS, init-value=0}, required-interface=IF_DiagApp_DisableDCMReqInfo
    provide port RTE_P_DCChrMgmt_BSTTxReqSts: nonqueued-sender-com-spec{data-element=tec_DCChrMgmt_BSTTxReqSts, init-value=0}, provided-interface=IF_DCChrMgmt_BSTTxReqSts
    require port RTE_R_ComM_BMSNegRlySts_Enum: nonqueued-receiver-com-spec{data-element=tec_ComM_BMSNegRlySts_Enum, filter=data-filter-type=ALWAYS, init-value=0}, required-interface=IF_ComM_BMSNegRlySts_Enum
    require port RTE_R_ComM_BMSPosRlySts_Enum: nonqueued-receiver-com-spec{data-element=tec_ComM_BMSPosRlySts_Enum, filter=data-filter-type=ALWAYS, init-value=0}, required-interface=IF_ComM_BMSPosRlySts_Enum
    4 x component:
      CtAp_ChrgMod: type=CtAp_ChrgMod
      CtAp_DCParMgmt: type=CtAp_DCParMgmt
      CtAp_ChrgSeqCtrl: type=CtAp_ChrgSeqCtrl
      CtAp_ChrgComM: type=CtAp_ChrgComM
    delegate CtAp_ChrgMod.RTE_P_DCChrMgmt_DcChrgnMod_Enum <-> outer port RTE_P_DCChrMgmt_DcChrgnMod_Enum
    delegate CtAp_ChrgSeqCtrl.RTE_P_DCChrMgmt_IRMeasEnaErr_Bus <-> outer port RTE_P_DCChrMgmt_IRMeasEnaErr_Bus
    delegate CtAp_ChrgSeqCtrl.RTE_P_DCChrMgmt_IRMeasSwtCtrl_Enum <-> outer port RTE_P_DCChrMgmt_IRMeasSwtCtrl_Enum
    delegate CtAp_ChrgSeqCtrl.RTE_P_DCChrMgmt_IRMeasDiErr_Bus <-> outer port RTE_P_DCChrMgmt_IRMeasDiErr_Bus
    delegate CtAp_ChrgSeqCtrl.RTE_P_DCChrMgmt_IRMeasEnaErrDTC_Bus <-> outer port RTE_P_DCChrMgmt_IRMeasEnaErrDTC_Bus
    delegate CtAp_ChrgSeqCtrl.RTE_P_DCChrMgmt_DcChrgnSts_Enum <-> outer port RTE_P_DCChrMgmt_DcChrgnSts_Enum
    delegate CtAp_ChrgSeqCtrl.RTE_P_DCChrMgmt_DcChrgStrt_Flg <-> outer port RTE_P_DCChrMgmt_DcChrgStrt_Flg
    delegate CtAp_ChrgSeqCtrl.RTE_P_DCChrMgmt_DCFCClsReq_Flg <-> outer port RTE_P_DCChrMgmt_DCFCClsReq_Flg
    delegate CtAp_ChrgSeqCtrl.RTE_P_DCChrMgmt_TxSts_Flg <-> outer port RTE_P_DCChrMgmt_TxSts_Flg
    delegate CtAp_ChrgSeqCtrl.RTE_P_DCChrMgmt_BROPrepFinshd_Enum <-> outer port RTE_P_DCChrMgmt_BROPrepFinshd_Enum
    delegate CtAp_ChrgSeqCtrl.RTE_P_DCChrMgmt_IRMeasDiErrDTC_Bus <-> outer port RTE_P_DCChrMgmt_IRMeasDiErrDTC_Bus
    delegate CtAp_DCParMgmt.RTE_P_DCChrMgmt_DCChrgnUDcReq_V <-> outer port RTE_P_DCChrMgmt_DCChrgnUDcReq_V
    delegate CtAp_DCParMgmt.RTE_P_DCChrMgmt_DcChrgnIDcReq_A <-> outer port RTE_P_DCChrMgmt_DcChrgnIDcReq_A
    delegate CtAp_ChrgComM.RTE_P_DCChrMgmt_MaxChrgUDc_V <-> outer port RTE_P_DCChrMgmt_MaxChrgUDc_V
    delegate CtAp_ChrgComM.RTE_R_ComM_CMLMaxOutpUDc_V <-> outer port RTE_R_ComM_CMLMaxOutpUDc_V
    delegate CtAp_ChrgComM.RTE_P_DCChrMgmt_BSMCellUDcErrSts_Enum <-> outer port RTE_P_DCChrMgmt_BSMCellUDcErrSts_Enum
    delegate CtAp_ChrgComM.RTE_P_DCChrMgmt_BSTChrgCnctErrSts_Enum <-> outer port RTE_P_DCChrMgmt_BSTChrgCnctErrSts_Enum
    delegate CtAp_ChrgComM.RTE_P_DCChrMgmt_BSTChkCC2UDcErr_Enum <-> outer port RTE_P_DCChrMgmt_BSTChkCC2UDcErr_Enum
    delegate CtAp_ChrgComM.RTE_P_DCChrMgmt_DcPortTempErrLvl1DTC_Bus <-> outer port RTE_P_DCChrMgmt_DcPortTempErrLvl1DTC_Bus
    delegate CtAp_ChrgComM.RTE_R_ComM_ChrgnRchTarTotUDc_Enum <-> outer port RTE_R_ComM_ChrgnRchTarTotUDc_Enum
    delegate CtAp_ChrgComM.RTE_P_DCChrMgmt_BSTIRErrStopSts_Enum <-> outer port RTE_P_DCChrMgmt_BSTIRErrStopSts_Enum
    delegate CtAp_ChrgComM.RTE_P_DCChrMgmt_BSTOtherErr_Enum <-> outer port RTE_P_DCChrMgmt_BSTOtherErr_Enum
    delegate CtAp_ChrgComM.RTE_R_IOAbs_CC2SigUDc_mV <-> outer port RTE_R_IOAbs_CC2SigUDc_mV
    delegate CtAp_ChrgComM.RTE_P_DCChrMgmt_BSTRchTarCellUDc_Enum <-> outer port RTE_P_DCChrMgmt_BSTRchTarCellUDc_Enum
    delegate CtAp_ChrgComM.RTE_P_DCChrMgmt_BSTRchTarTotUDc_Enum <-> outer port RTE_P_DCChrMgmt_BSTRchTarTotUDc_Enum
    delegate CtAp_ChrgComM.RTE_R_LvMgmt_BSBattUDcNorm_Flg <-> outer port RTE_R_LvMgmt_BSBattUDcNorm_Flg
    delegate CtAp_ChrgComM.RTE_P_DCChrMgmt_DcPortTempSnsrErr_Bus <-> outer port RTE_P_DCChrMgmt_DcPortTempSnsrErr_Bus
    delegate CtAp_ChrgComM.RTE_P_DCChrMgmt_BSTChrgPrmErr_Enum <-> outer port RTE_P_DCChrMgmt_BSTChrgPrmErr_Enum
    delegate CtAp_ChrgComM.RTE_R_ErrMgmt_VCUHVILErr_Flg <-> outer port RTE_R_ErrMgmt_VCUHVILErr_Flg
    delegate CtAp_ChrgComM.RTE_R_ComM_BMSSOCErrLoSts_Enum <-> outer port RTE_R_ComM_BMSSOCErrLoSts_Enum
    delegate CtAp_ChrgComM.RTE_P_DCChrMgmt_DcPortTempErrLvl2_Bus <-> outer port RTE_P_DCChrMgmt_DcPortTempErrLvl2_Bus
    delegate CtAp_ChrgComM.RTE_P_DCChrMgmt_MaxChrgIDc_A <-> outer port RTE_P_DCChrMgmt_MaxChrgIDc_A
    delegate CtAp_ChrgComM.RTE_P_DCChrMgmt_BEMRxCROTmtDTC_Bus <-> outer port RTE_P_DCChrMgmt_BEMRxCROTmtDTC_Bus
    delegate CtAp_ChrgComM.RTE_P_DCChrMgmt_BSTUDcErrSts_Enum <-> outer port RTE_P_DCChrMgmt_BSTUDcErrSts_Enum
    delegate CtAp_ChrgComM.RTE_R_ComM_BMSSOCErrHiSts_Enum <-> outer port RTE_R_ComM_BMSSOCErrHiSts_Enum
    delegate CtAp_ChrgComM.RTE_P_DCChrMgmt_BSTChrgrStopSts_Enum <-> outer port RTE_P_DCChrMgmt_BSTChrgrStopSts_Enum
    delegate CtAp_ChrgComM.RTE_P_DCChrMgmt_BEMRxCROPrepdTmt_Bus <-> outer port RTE_P_DCChrMgmt_BEMRxCROPrepdTmt_Bus
    delegate CtAp_ChrgComM.RTE_R_ComM_BMSErrInfoTimeoutInfo_Bus <-> outer port RTE_R_ComM_BMSErrInfoTimeoutInfo_Bus
    delegate CtAp_ChrgComM.RTE_P_DCChrMgmt_BEMRxCCSTmtDTC_Bus <-> outer port RTE_P_DCChrMgmt_BEMRxCCSTmtDTC_Bus
    delegate CtAp_ChrgComM.RTE_P_DCChrMgmt_BEMRxCSTTmt_Bus <-> outer port RTE_P_DCChrMgmt_BEMRxCSTTmt_Bus
    delegate CtAp_ChrgComM.RTE_R_ComM_BMSCellHiTempErr_Enum <-> outer port RTE_R_ComM_BMSCellHiTempErr_Enum
    delegate CtAp_ChrgComM.RTE_R_ComM_PODSts01TimeoutInfo_Bus <-> outer port RTE_R_ComM_PODSts01TimeoutInfo_Bus
    delegate CtAp_ChrgComM.RTE_R_ComM_MaxCellUDcErrSts_Enum <-> outer port RTE_R_ComM_MaxCellUDcErrSts_Enum
    delegate CtAp_ChrgComM.RTE_R_ComM_BMSHVILSts_Flg <-> outer port RTE_R_ComM_BMSHVILSts_Flg
    delegate CtAp_ChrgComM.RTE_P_DCChrMgmt_BSTHvRlyErrSts_Enum <-> outer port RTE_P_DCChrMgmt_BSTHvRlyErrSts_Enum
    delegate CtAp_ChrgComM.RTE_P_DCChrMgmt_BEMRxCCSTmt_Bus <-> outer port RTE_P_DCChrMgmt_BEMRxCCSTmt_Bus
    delegate CtAp_ChrgComM.RTE_P_DCChrMgmt_BEMRxCMLTmt_Bus <-> outer port RTE_P_DCChrMgmt_BEMRxCMLTmt_Bus
    delegate CtAp_ChrgComM.RTE_R_ComM_AbortFltBattTemp_Enum <-> outer port RTE_R_ComM_AbortFltBattTemp_Enum
    delegate CtAp_ChrgComM.RTE_R_ComM_RxSts_Flg <-> outer port RTE_R_ComM_RxSts_Flg
    delegate CtAp_ChrgComM.RTE_R_ComM_PODDcPosRlySts_Enum <-> outer port RTE_R_ComM_PODDcPosRlySts_Enum
    delegate CtAp_ChrgComM.RTE_P_DCChrMgmt_DcPortTempErrLvl2DTC_Bus <-> outer port RTE_P_DCChrMgmt_DcPortTempErrLvl2DTC_Bus
    delegate CtAp_ChrgComM.RTE_P_DCChrMgmt_BEMRxCMLTmtDTC_Bus <-> outer port RTE_P_DCChrMgmt_BEMRxCMLTmtDTC_Bus
    delegate CtAp_ChrgComM.RTE_R_ChrMgmt_VCUCalcdPODIDc_A <-> outer port RTE_R_ChrMgmt_VCUCalcdPODIDc_A
    delegate CtAp_ChrgComM.RTE_R_ComM_DcInletBSnsrSts_Enum <-> outer port RTE_R_ComM_DcInletBSnsrSts_Enum
    delegate CtAp_ChrgComM.RTE_P_DCChrMgmt_BSMSOCErrSts_Enum <-> outer port RTE_P_DCChrMgmt_BSMSOCErrSts_Enum
    delegate CtAp_ChrgComM.RTE_R_ComM_BMSErrRlySts_Enum <-> outer port RTE_R_ComM_BMSErrRlySts_Enum
    delegate CtAp_ChrgComM.RTE_R_ComM_DcInletASnsrSts_Enum <-> outer port RTE_R_ComM_DcInletASnsrSts_Enum
    delegate CtAp_ChrgComM.RTE_P_DCChrMgmt_BEMRxCSDTmtDTC_Bus <-> outer port RTE_P_DCChrMgmt_BEMRxCSDTmtDTC_Bus
    delegate CtAp_ChrgComM.RTE_R_ComM_AbortErrIDc_Enum <-> outer port RTE_R_ComM_AbortErrIDc_Enum
    delegate CtAp_ChrgComM.RTE_R_ComM_CMLMinOutpUDc_V <-> outer port RTE_R_ComM_CMLMinOutpUDc_V
    delegate CtAp_ChrgComM.RTE_R_ComM_PODDCFCUDc_V <-> outer port RTE_R_ComM_PODDCFCUDc_V
    delegate CtAp_ChrgComM.RTE_P_DCChrMgmt_MinChrgIDc_A <-> outer port RTE_P_DCChrMgmt_MinChrgIDc_A
    delegate CtAp_ChrgComM.RTE_R_ChrMgmt_ChrgSts_Enum <-> outer port RTE_R_ChrMgmt_ChrgSts_Enum
    delegate CtAp_ChrgComM.RTE_P_DCChrMgmt_BSTBMSCnctOvrTemp_Enum <-> outer port RTE_P_DCChrMgmt_BSTBMSCnctOvrTemp_Enum
    delegate CtAp_ChrgComM.RTE_R_ComM_ChrgnRchTarCellUDc_Enum <-> outer port RTE_R_ComM_ChrgnRchTarCellUDc_Enum
    delegate CtAp_ChrgComM.RTE_R_ComM_CMLMinOutpIDc_A <-> outer port RTE_R_ComM_CMLMinOutpIDc_A
    delegate CtAp_ChrgComM.RTE_P_DCChrMgmt_DcChrgrCpbyPassd_Flg <-> outer port RTE_P_DCChrMgmt_DcChrgrCpbyPassd_Flg
    delegate CtAp_ChrgComM.RTE_P_DCChrMgmt_DcPortTempErrLvl1_Bus <-> outer port RTE_P_DCChrMgmt_DcPortTempErrLvl1_Bus
    delegate CtAp_ChrgComM.RTE_R_ComM_DcInletATemp_C <-> outer port RTE_R_ComM_DcInletATemp_C
    delegate CtAp_ChrgComM.RTE_P_DCChrMgmt_BEMRxCROPrepdTmtDTC_Bus <-> outer port RTE_P_DCChrMgmt_BEMRxCROPrepdTmtDTC_Bus
    delegate CtAp_ChrgComM.RTE_R_ChrMgmt_DcChrgCmplSts_Enum <-> outer port RTE_R_ChrMgmt_DcChrgCmplSts_Enum
    delegate CtAp_ChrgComM.RTE_P_DCChrMgmt_BSTOutpCnctOvrTemp_Enum <-> outer port RTE_P_DCChrMgmt_BSTOutpCnctOvrTemp_Enum
    delegate CtAp_ChrgComM.RTE_P_DCChrMgmt_BEMRxCSDTmt_Bus <-> outer port RTE_P_DCChrMgmt_BEMRxCSDTmt_Bus
    delegate CtAp_ChrgComM.RTE_R_ComM_ChrgnRchSetVal_Enum <-> outer port RTE_R_ComM_ChrgnRchSetVal_Enum
    delegate CtAp_ChrgComM.RTE_P_DCChrMgmt_MinChrgUDc_V <-> outer port RTE_P_DCChrMgmt_MinChrgUDc_V
    delegate CtAp_ChrgComM.RTE_P_DCChrMgmt_BSTRchTarSOC_Enum <-> outer port RTE_P_DCChrMgmt_BSTRchTarSOC_Enum
    delegate CtAp_ChrgComM.RTE_P_DCChrMgmt_BEMRxCRMPrepdTmtDTC_Bus <-> outer port RTE_P_DCChrMgmt_BEMRxCRMPrepdTmtDTC_Bus
    delegate CtAp_ChrgComM.RTE_P_DCChrMgmt_BSMOutpCnctErrSts_Enum <-> outer port RTE_P_DCChrMgmt_BSMOutpCnctErrSts_Enum
    delegate CtAp_ChrgComM.RTE_P_DCChrMgmt_BSTBattOvrTempErr_Enum <-> outer port RTE_P_DCChrMgmt_BSTBattOvrTempErr_Enum
    delegate CtAp_ChrgComM.RTE_P_DCChrMgmt_BSMIRErrSts_Enum <-> outer port RTE_P_DCChrMgmt_BSMIRErrSts_Enum
    delegate CtAp_ChrgComM.RTE_P_DCChrMgmt_BSMBattTempHiErrSts_Enum <-> outer port RTE_P_DCChrMgmt_BSMBattTempHiErrSts_Enum
    delegate CtAp_ChrgComM.RTE_R_ComM_AbortErrUDc_Enum <-> outer port RTE_R_ComM_AbortErrUDc_Enum
    delegate CtAp_ChrgComM.RTE_P_DCChrMgmt_BSMChrgnIDcErrSts_Enum <-> outer port RTE_P_DCChrMgmt_BSMChrgnIDcErrSts_Enum
    delegate CtAp_ChrgComM.RTE_P_DCChrMgmt_BEMTxReqSts_Enum <-> outer port RTE_P_DCChrMgmt_BEMTxReqSts_Enum
    delegate CtAp_ChrgComM.RTE_R_ComM_BMSSts01ErrInfo_Bus <-> outer port RTE_R_ComM_BMSSts01ErrInfo_Bus
    delegate CtAp_ChrgComM.RTE_R_ComM_MinCellUDcErrSts_Enum <-> outer port RTE_R_ComM_MinCellUDcErrSts_Enum
    delegate CtAp_ChrgComM.RTE_R_ComM_CANBusOffInfo_Bus <-> outer port RTE_R_ComM_CANBusOffInfo_Bus
    delegate CtAp_ChrgComM.RTE_P_DCChrMgmt_BEMRxCRMTmtDTC_Bus <-> outer port RTE_P_DCChrMgmt_BEMRxCRMTmtDTC_Bus
    delegate CtAp_ChrgComM.RTE_R_ComM_AbortFltBMSTemp_Enum <-> outer port RTE_R_ComM_AbortFltBMSTemp_Enum
    delegate CtAp_ChrgComM.RTE_P_DCChrMgmt_BSTIDcErrSts_Enum <-> outer port RTE_P_DCChrMgmt_BSTIDcErrSts_Enum
    delegate CtAp_ChrgComM.RTE_P_DCChrMgmt_BEMRxCRMTmt_Bus <-> outer port RTE_P_DCChrMgmt_BEMRxCRMTmt_Bus
    delegate CtAp_ChrgComM.RTE_R_ComM_BMSInslaErrLvl_Enum <-> outer port RTE_R_ComM_BMSInslaErrLvl_Enum
    delegate CtAp_ChrgComM.RTE_R_ComM_ChrgnIDcErrSts_Enum <-> outer port RTE_R_ComM_ChrgnIDcErrSts_Enum
    delegate CtAp_ChrgComM.RTE_R_ComM_CMLMaxOutpIDc_A <-> outer port RTE_R_ComM_CMLMaxOutpIDc_A
    delegate CtAp_ChrgComM.RTE_P_DCChrMgmt_BEMRxCROTmt_Bus <-> outer port RTE_P_DCChrMgmt_BEMRxCROTmt_Bus
    delegate CtAp_ChrgComM.RTE_P_DCChrMgmt_DcPortTempSnsrErrDTC_Bus <-> outer port RTE_P_DCChrMgmt_DcPortTempSnsrErrDTC_Bus
    delegate CtAp_ChrgComM.RTE_R_ComM_DcInletBTemp_C <-> outer port RTE_R_ComM_DcInletBTemp_C
    delegate CtAp_ChrgComM.RTE_P_DCChrMgmt_BSMChrgAllwbl_Flg <-> outer port RTE_P_DCChrMgmt_BSMChrgAllwbl_Flg
    delegate CtAp_ChrgComM.RTE_P_DCChrMgmt_BEMRxCRMPrepdTmt_Bus <-> outer port RTE_P_DCChrMgmt_BEMRxCRMPrepdTmt_Bus
    delegate CtAp_ChrgComM.RTE_P_DCChrMgmt_BEMRxCSTTmtDTC_Bus <-> outer port RTE_P_DCChrMgmt_BEMRxCSTTmtDTC_Bus
    delegate CtAp_ChrgMod.RTE_R_ChrMgmt_PreheatSts_Enum <-> outer port RTE_R_ChrMgmt_PreheatSts_Enum
    delegate CtAp_ChrgMod.RTE_R_ComM_BMSBattDispSOC_pct <-> outer port RTE_R_ComM_BMSBattDispSOC_pct
    connect CtAp_ChrgSeqCtrl.RTE_P_DCChrMgmt_DcChrgnSts_Enum -> CtAp_ChrgMod.RTE_R_DCChrMgmt_DcChrgnSts_Enum
    delegate CtAp_ChrgMod.RTE_R_ComM_BattChrgnModReq_Enum <-> outer port RTE_R_ComM_BattChrgnModReq_Enum
    delegate CtAp_ChrgSeqCtrl.RTE_R_ChrMgmt_VCUCalcdPODInitIDc_A <-> outer port RTE_R_ChrMgmt_VCUCalcdPODInitIDc_A
    delegate CtAp_ChrgSeqCtrl.RTE_R_HvMgmt_DCFCWrkModActSts_Enum <-> outer port RTE_R_HvMgmt_DCFCWrkModActSts_Enum
    delegate CtAp_ChrgSeqCtrl.RTE_R_ComM_CRMRecgRes_Enum <-> outer port RTE_R_ComM_CRMRecgRes_Enum
    delegate CtAp_ChrgSeqCtrl.RTE_R_ChrMgmt_DcChrgAllwd_Flg <-> outer port RTE_R_ChrMgmt_DcChrgAllwd_Flg
    delegate CtAp_ChrgSeqCtrl.RTE_R_ComM_BMSIRDetnSts_Enum <-> outer port RTE_R_ComM_BMSIRDetnSts_Enum
    delegate CtAp_ChrgSeqCtrl.RTE_R_ComM_CROPrepRdy_Enum <-> outer port RTE_R_ComM_CROPrepRdy_Enum
    delegate CtAp_ChrgSeqCtrl.RTE_R_ComM_RxSts_Flg <-> outer port RTE_R_ComM_RxSts_Flg
    delegate CtAp_ChrgSeqCtrl.RTE_R_ChrMgmt_ChrgSts_Enum <-> outer port RTE_R_ChrMgmt_ChrgSts_Enum
    delegate CtAp_ChrgSeqCtrl.RTE_R_ChrMgmt_DcChrgCmplSts_Enum <-> outer port RTE_R_ChrMgmt_DcChrgCmplSts_Enum
    delegate CtAp_ChrgSeqCtrl.RTE_R_ChrMgmt_PreheatSts_Enum <-> outer port RTE_R_ChrMgmt_PreheatSts_Enum
    delegate CtAp_ChrgSeqCtrl.RTE_R_ComM_CANBusOffInfo_Bus <-> outer port RTE_R_ComM_CANBusOffInfo_Bus
    delegate CtAp_ChrgSeqCtrl.RTE_R_LvMgmt_BSBattUDcNorm_Flg <-> outer port RTE_R_LvMgmt_BSBattUDcNorm_Flg
    connect CtAp_ChrgMod.RTE_P_DCChrMgmt_DcChrgnMod_Enum -> CtAp_DCParMgmt.RTE_R_DCChrMgmt_DcChrgnMod_Enum
    delegate CtAp_DCParMgmt.RTE_R_ErrMgmt_DcPause_Flg <-> outer port RTE_R_ErrMgmt_DcPause_Flg
    delegate CtAp_DCParMgmt.RTE_R_ComM_BMSBattAllowChrgIDc_A <-> outer port RTE_R_ComM_BMSBattAllowChrgIDc_A
    delegate CtAp_DCParMgmt.RTE_R_ComM_BMSBattLnkUDc_V <-> outer port RTE_R_ComM_BMSBattLnkUDc_V
    delegate CtAp_DCParMgmt.RTE_R_ComM_BMSBattPckUDc_V <-> outer port RTE_R_ComM_BMSBattPckUDc_V
    delegate CtAp_DCParMgmt.RTE_R_EgyMgmt_DCDCPwrCnsCalcn_Kw <-> outer port RTE_R_EgyMgmt_DCDCPwrCnsCalcn_Kw
    delegate CtAp_DCParMgmt.RTE_R_EgyMgmt_PackPTCPwrCnsCalcn_Kw <-> outer port RTE_R_EgyMgmt_PackPTCPwrCnsCalcn_Kw
    delegate CtAp_DCParMgmt.RTE_R_EgyMgmt_ACSysPwrCnsCalcn_Kw <-> outer port RTE_R_EgyMgmt_ACSysPwrCnsCalcn_Kw
    delegate CtAp_DCParMgmt.RTE_R_ComM_BMSBattMaxChrgnUDc_V <-> outer port RTE_R_ComM_BMSBattMaxChrgnUDc_V
    delegate CtAp_DCParMgmt.RTE_R_ChrMgmt_PreheatSts_Enum <-> outer port RTE_R_ChrMgmt_PreheatSts_Enum
    delegate CtAp_DCParMgmt.RTE_R_ComM_CMLMaxOutpIDc_A <-> outer port RTE_R_ComM_CMLMaxOutpIDc_A
    delegate CtAp_DCParMgmt.RTE_R_ModMgmt_HvSts_Enum <-> outer port RTE_R_ModMgmt_HvSts_Enum
    connect CtAp_ChrgComM.RTE_P_DCChrMgmt_DcPortTempErrLvl1_Bus -> CtAp_DCParMgmt.RTE_R_DCChrMgmt_DcPortTempErrLvl1_Bus
    connect CtAp_ChrgComM.RTE_P_DCChrMgmt_BEMTxReqSts_Enum -> CtAp_ChrgSeqCtrl.RTE_R_DCChrMgmt_BEMTxReqSts_Enum
    connect CtAp_ChrgComM.RTE_P_DCChrMgmt_DcChrgrCpbyPassd_Flg -> CtAp_ChrgSeqCtrl.RTE_R_DCChrMgmt_DcChrgrCpbyPassd_Flg
    connect CtAp_ChrgSeqCtrl.RTE_P_DCChrMgmt_DcChrgnSts_Enum -> CtAp_ChrgComM.RTE_R_DCChrMgmt_DcChrgnSts_Enum
    connect CtAp_ChrgSeqCtrl.RTE_P_DCChrMgmt_TxSts_Flg -> CtAp_ChrgComM.RTE_R_DCChrMgmt_TxSts_Flg
    connect CtAp_ChrgSeqCtrl.RTE_P_DCChrMgmt_BROPrepFinshd_Enum -> CtAp_ChrgComM.RTE_R_DCChrMgmt_BROPrepFinshd_Enum
    delegate CtAp_ChrgComM.RTE_R_DiagApp_DisableDCMReqInfo <-> outer port RTE_R_DiagApp_DisableDCMReqInfo
    delegate CtAp_ChrgSeqCtrl.RTE_R_DiagApp_DisableDCMReqInfo <-> outer port RTE_R_DiagApp_DisableDCMReqInfo
    delegate CtAp_ChrgComM.RTE_P_DCChrMgmt_BSTTxReqSts <-> outer port RTE_P_DCChrMgmt_BSTTxReqSts
    delegate CtAp_DCParMgmt.RTE_R_ComM_BMSNegRlySts_Enum <-> outer port RTE_R_ComM_BMSNegRlySts_Enum
    delegate CtAp_DCParMgmt.RTE_R_ComM_BMSPosRlySts_Enum <-> outer port RTE_R_ComM_BMSPosRlySts_Enum
